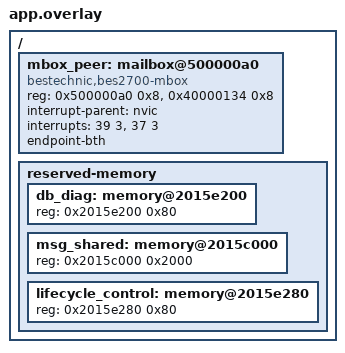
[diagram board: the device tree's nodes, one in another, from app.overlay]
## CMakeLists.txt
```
# SPDX-License-Identifier: Apache-2.0
cmake_minimum_required(VERSION 3.20.0)
find_package(Zephyr REQUIRED HINTS $ENV{ZEPHYR_BASE})
project(bes2700_bth_dual_message)
if(NOT CONFIG_GPIO_BES2700YP)
  target_sources(app PRIVATE
    ${CMAKE_CURRENT_LIST_DIR}/../../../platforms/bes2700yp/boot/service_contract.c
    ${CMAKE_CURRENT_LIST_DIR}/../../../platforms/bes2700yp/resources/contract.c)
endif()
target_sources(app PRIVATE
  ${CMAKE_CURRENT_LIST_DIR}/../../../platforms/bes2700yp/resources/client.c
  ${CMAKE_CURRENT_LIST_DIR}/../../../platforms/bes2700yp/resources/uart_contract.c
  ${CMAKE_CURRENT_LIST_DIR}/../../../platforms/bes2700yp/resources/uart_client.c
  ${CMAKE_CURRENT_LIST_DIR}/../../../platforms/bes2700yp/resources/arbitration_contract.c
  ${CMAKE_CURRENT_LIST_DIR}/../../../platforms/bes2700yp/resources/arbitration_client.c
  ${CMAKE_CURRENT_LIST_DIR}/../../../platforms/bes2700yp/resources/probe.c)
zephyr_get(DUAL_GENERATED_DIR SYSBUILD)
if(CONFIG_BES2700_M55_RESTART)
  target_sources(app PRIVATE src/restart.c
    ${CMAKE_CURRENT_LIST_DIR}/../../../platforms/bes2700yp/lifecycle/manager.c
    ${CMAKE_CURRENT_LIST_DIR}/../../../platforms/bes2700yp/lifecycle/health.c)
else()
  target_sources(app PRIVATE src/main.c)
endif()
if(NOT DUAL_GENERATED_DIR)
  message(FATAL_ERROR "DUAL_GENERATED_DIR is required; use west build --sysbuild")
endif()
target_include_directories(app PRIVATE ${DUAL_GENERATED_DIR})

target_sources(app PRIVATE ${CMAKE_CURRENT_LIST_DIR}/../../../platforms/bes2700yp/ipc/worker.c)
target_compile_definitions(app PRIVATE CC_BTH=1)
target_include_directories(app PRIVATE ${CMAKE_CURRENT_LIST_DIR}/../../../platforms/bes2700yp/ipc)

get_filename_component(bes_workspace ${CMAKE_CURRENT_LIST_DIR}/../../../.. ABSOLUTE)
get_filename_component(bes_build ${PROJECT_BINARY_DIR}/.. ABSOLUTE)
zephyr_compile_options(-ffile-prefix-map=${bes_workspace}=workspace
  -ffile-prefix-map=${bes_build}=build
  $<$<COMPILE_LANGUAGE:ASM>:-Wa,--debug-prefix-map=${bes_workspace}=workspace>
  $<$<COMPILE_LANGUAGE:ASM>:-Wa,--debug-prefix-map=${bes_build}=build>)

if(CONFIG_BES2700YP_GPIO_VALIDATION GREATER 0)
  if(CONFIG_GPIO_BES2700YP_IRQ)
    target_sources(app PRIVATE src/gpio_irq_validation.c)
  elseif(CONFIG_BES2700_M55_RESTART)
    target_sources(app PRIVATE src/gpio_restart.c)
  else()
    target_sources(app PRIVATE src/gpio_validation.c)
  endif()
  if(NOT CONFIG_GPIO_BES2700YP)
    target_sources(app PRIVATE
      ${CMAKE_CURRENT_LIST_DIR}/../../../platforms/bes2700yp/resources/gpio_client.c
      ${CMAKE_CURRENT_LIST_DIR}/../../../platforms/bes2700yp/resources/gpio_contract.c)
  endif()
endif()
```

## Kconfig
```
# SPDX-License-Identifier: Apache-2.0

mainmenu "BES2700YP dual-core validation"
source "Kconfig.zephyr"
config DUAL_CC_PAIR
 hex "Message image pair identity"
 default 0
config DUAL_M55_BUILD
 hex "M55 image source identity"
 default 0

config BTH_LOG_PREFIX
 bool
 default y
config DUAL_DURATION_SECONDS
 int "Dual heartbeat duration in seconds"
 range 600 3610
 default 3610

config DUAL_IPC_SECONDS
 int "Active concurrent traffic duration"
 range 600 3600
 default 3600

config DUAL_MSG_MODE
 int "Message validation: 1=sequential, 2=concurrent, 3=negative"
 range 1 3
 default 1

config BES2700_M55_RESTART
 bool "Validate RAM-retained M55 CPU restart"
 default n

config BES2700_M55_FAULT_CASE
 int "M55 fault injection: 0=off, 1=READY, 2=heartbeat, 3=IPC, 4=QUIESCE, 5=fatal, 6=lost fatal"
 range 0 6
 default 0
 help
   Validation only. Nonzero values require the retained-RAM lifecycle.
   Select a controlled peer fault in the validation application only.

config BES2700_M55_RECOVERY
 bool "Validate one M55 recovery after isolation"
 depends on BES2700_M55_RESTART && BES2700_M55_FAULT_CASE > 0
 default n
 help
   Rebuild the BTH worker and reload M55 once with a new session.
   Inject only in session 1; failed recovery remains isolated.

config BES2700_M55_RECOVERY_FAIL_STEP
 int "Recovery failure injection: 0=off, 1=REPARK, 3=load, 5=new READY"
 range 0 5
 default 0
 help
   Validation only. Values 1 and 3 inject an operation failure before
   touching hardware or loading RAM. Value 5 stops the replacement
   M55 before READY. Profiles reject other nonzero values.
```

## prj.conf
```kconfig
CONFIG_BOOT_BANNER=n
CONFIG_LOG=n
CONFIG_PRINTK=n
CONFIG_CONSOLE=n
CONFIG_ASSERT=y
CONFIG_INIT_STACKS=y
CONFIG_THREAD_STACK_INFO=y
CONFIG_STACK_SENTINEL=y
CONFIG_TICKLESS_KERNEL=n
CONFIG_SYS_CLOCK_TICKS_PER_SEC=1000
CONFIG_MAIN_STACK_SIZE=3072
CONFIG_ISR_STACK_SIZE=2048
CONFIG_PM=n
CONFIG_ARM_MPU=n
CONFIG_HW_STACK_PROTECTION=n
CONFIG_FPU=n
CONFIG_SERIAL=n

CONFIG_MBOX=y
CONFIG_MBOX_BES2700=y
```

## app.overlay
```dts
/* Copyright The Zephyr Project Contributors */
/* SPDX-License-Identifier: Apache-2.0 */

/ {
	mbox_peer: mailbox@500000a0 {
		compatible = "bestechnic,bes2700-mbox";
		reg = <0x500000a0 0x8>, <0x40000134 0x8>;
		reg-names = "sys", "bth";
		interrupt-parent = <&nvic>;
		interrupts = <39 3>, <37 3>;
		endpoint-bth;
		interrupt-names = "rx", "tx-done";
		#mbox-cells = <1>;
		status = "okay";
	};
};

/ { reserved-memory { db_diag: memory@2015e200 { reg = <0x2015e200 0x80>; }; }; };
/ { reserved-memory { msg_shared: memory@2015c000 { reg = <0x2015c000 0x2000>; }; }; };

/* Last shared writer publishes quiescence before CPU reset. */
/ { reserved-memory { lifecycle_control: memory@2015e280 { reg = <0x2015e280 0x80>; }; }; };
```

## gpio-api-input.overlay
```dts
/* SPDX-License-Identifier: Apache-2.0 */
&aon_gpio {
	status = "okay";
	gpio-reserved-ranges = <0 16>;
};
```

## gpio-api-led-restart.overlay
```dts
/* SPDX-License-Identifier: Apache-2.0 */
&aon_gpio {
	status = "okay";
};
```

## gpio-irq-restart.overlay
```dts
/* SPDX-License-Identifier: Apache-2.0 */
&aon_gpio {
	status = "okay";
	interrupt-parent = <&nvic>;
	interrupts = <44 3>;
	gpio-reserved-ranges = <0 16>;
};
```

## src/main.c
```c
/* SPDX-License-Identifier: Apache-2.0 */
#include <zephyr/kernel.h>
#include <cmsis_core.h>
#include <bes2700_dual_boot.h>
#include <bes2700_dual_image.h>
#include "bth_contract.h"
#include "m55_payload.h"
#include "message.h"
#include <bes2700_dual_doorbell.h>
#include <bes2700_observation.h>
#include <bes2700yp_resources.h>
#if CONFIG_BES2700YP_GPIO_VALIDATION
#include <bes2700yp_gpio_validation.h>
#endif
#define SECONDS CONFIG_DUAL_DURATION_SECONDS
BUILD_ASSERT(SECONDS==(CONFIG_DUAL_MSG_MODE!=2?600:CONFIG_DUAL_IPC_SECONDS+10));
_Static_assert(BTH_LOG_ADDR >= DUAL_HW_ADDR + sizeof(struct dual_hw), "log/hardware overlap");
_Static_assert(BTH_LOG_ADDR + sizeof(struct bth_log_clock) <= BTH_DIAG_BASE + 0x1000, "log page overflow");
static int (*service)(uint32_t, uint32_t);
static uint32_t parked;
static volatile uint32_t timer_count;
static void tick(struct k_timer *t) { ARG_UNUSED(t); timer_count++; bth_log_poll(); }
K_TIMER_DEFINE(timer, tick, NULL);
static void field(const char *name, uint32_t n) { bth_puts(name); bth_dec(n); }
static void stage(uint32_t id, uint32_t rc)
{ bth_log_begin(rc?'E':'I',"LOADER","MAIN"); bth_puts("zephyr_dual stage"); field(" id=",id); field(" rc=",rc); bth_end(); }
static void finish(uint32_t samples, uint32_t rc)
{
#if CONFIG_BES2700YP_GPIO_VALIDATION
 bes_gpio_validation_end();
#endif
 q_stop();
 k_timer_stop(&timer);
 if(CONFIG_DUAL_MSG_MODE==2 || rc) {
  bth_log_begin(rc?'E':'I',"KERN","MAIN");
  bth_puts("zephyr_dual result");field(" pass=",rc==0);field(" samples=",samples);field(" rc=",rc);bth_end();
 }
 /* Do not touch shared RAM after stopping the peer. Power remains enabled. */
 if (parked && service) { (void)service(DUAL_STOP,0); }
 /* The periodic clock sampler has stopped; future faults must print NA. */
 bth_log_reset();
}
static void observe_begin(const char *kind, uint32_t rc)
{
 bth_log_begin(rc?'E':'I',"OBSERVE","MAIN");bth_puts("zephyr_observe ");bth_puts(kind);
}
/* Workers have finished. Read the actual AXI publications again, including
 * their seqlocks, instead of accepting only the cached final report. */
static int observe_traffic(const struct q_report *report)
{
 if(!report->finished || report->rc || !report->session) { return 95; }
 for(unsigned side=0;side<2;side++) {
  volatile struct bi_ring *ring=(void *)(uintptr_t)(BI_BASE+4096U*side);
  if(!bi_guards_ok(ring) || ring->head!=ring->tail) { return 95; }
  volatile struct q_state *shared=&ring->state;
  struct q_state copy;uint32_t seq=shared->seq;__DMB();
  if(seq&1) { return 95; }
  uint32_t *d=(void *)&copy;volatile uint32_t *src=(void *)shared;
  for(unsigned i=0;i<sizeof(copy)/4;i++) { d[i]=src[i]; }
  __DMB();if(seq!=shared->seq || copy.seq!=seq) { return 95; }
  const struct q_state *expected=side?&report->m55:&report->bth;
#define CHECK_TERMINAL(n) if(copy.n!=expected->n) { return 95; }
  Q_FIELDS(CHECK_TERMINAL)
#undef CHECK_TERMINAL
  if(copy.error || copy.guard!=Q_META_GUARD) { return 95; }
 }
 return 0;
}
static int observe_checkpoint(struct bes_observation *o, unsigned scope, uint32_t ms,
                              uint32_t samples, const struct q_report *report)
{
 int rc=observe_traffic(report);
 observe_begin("traffic",rc);field(" scope=",scope);field(" session=",report->session);
 field(" finished=",report->finished);field(" live=",!rc);field(" rc=",rc);bth_end();
 observe_begin("result",rc);field(" version=",BES_OBSERVATION_VERSION);field(" scope=",scope);
 field(" pass=",!rc);field(" session=",report->session);field(" functional_ms=",o->functional_ms);
 field(" ms=",ms);field(" samples=",samples);field(" rc=",rc);bth_end();
 return rc;
}
static int read_peer(struct dual_status *s)
{
 for (unsigned retry=0; retry<1000; retry++) {
  uint32_t seq=DUAL_STATUS->seq;
  if (seq&1) { continue; }
  __DMB();
  uint32_t *dst=(uint32_t *)s; volatile uint32_t *src=(volatile uint32_t *)DUAL_STATUS;
  for (unsigned i=0; i<sizeof(*s)/4; i++) { dst[i]=src[i]; }
  __DMB();
  if (seq==DUAL_STATUS->seq && seq==s->seq) { return 0; }
 }
 return -1;
}
static void diagnostics(uint32_t id, uint32_t elapsed, uint32_t good, uint32_t bad)
{
 int hr=service(DUAL_SNAPSHOT,DUAL_HW_ADDR);
 bth_log_begin(hr?'E':'I',"LOADER","MAIN");
 bth_puts("zephyr_dual hw"); field(" id=",id); field(" rc=",hr?1:0);
 const volatile struct dual_hw *h=DUAL_HW;
#define HW(name) bth_field(" " #name "=",h->name)
 HW(phase); HW(core_vtor); HW(reset_set); HW(reset_clr); HW(ram_sel0); HW(ram_sel1);
 HW(oclk); HW(oreset); HW(sysclk); HW(vector_sp); HW(vector_pc); HW(release_sp); HW(release_pc);
#undef HW
 bth_end();
 /* Trace is for localization. Raw values can change while peer runs. */
 struct dual_trace d;
 volatile uint32_t *src=(void *)DUAL_TRACE;
 uint32_t *dst=(void *)&d;
 for (unsigned i=0;i<sizeof(d)/4;i++) { dst[i]=src[i]; }
 __DMB();
 uint32_t stable=d.stage==DUAL_TRACE->stage;
 bth_log_begin('I',"LOADER","MAIN");
 bth_puts("zephyr_dual diag"); field(" id=",id); field(" elapsed=",elapsed);
 field(" reads=",good); field(" retries=",bad); field(" stable=",stable);
 bth_field(" seq=",DUAL_STATUS->seq); bth_field(" magic=",DUAL_STATUS->magic);
#define TRACE(name) bth_field(" " #name "=",d.name)
 TRACE(stage); TRACE(cpuid); TRACE(vtor); TRACE(msp); TRACE(psp); TRACE(control);
 TRACE(primask); TRACE(basepri); TRACE(ccr); TRACE(mpu); TRACE(cpacr); TRACE(cfsr);
 TRACE(hfsr); TRACE(shcsr); TRACE(mmfar); TRACE(bfar); TRACE(icsr); TRACE(reason);
 TRACE(msplim); TRACE(psplim); TRACE(pc); TRACE(lr); TRACE(xpsr); TRACE(esf_valid);
#undef TRACE
 bth_end();
}
static int peer_ok(const struct dual_status *s)
{
 return s->magic==DUAL_MAGIC && s->layout==DUAL_LAYOUT && s->build==M55_BUILD_ID &&
        s->stage==2 && s->hz==DUAL_HZ && s->guard==DUAL_GUARD && !s->error &&
        (s->cpuid&0xff00fff0U)==0x4100d220U && s->vtor==DUAL_ITCM && s->control==2 &&
        !s->primask && !s->basepri && !s->mpu && !(s->ccr & ((1U<<16)|(1U<<17))) && s->stack>=128;
}
int main(void)
{
 bth_stage("main");
 if (bes_resource_probe(0)) { finish(0,96); return 0; }
 bth_log_begin('I',"LOADER","MAIN");
 bth_puts("zephyr_dual begin version=3 test=8"); bth_field(" build=",BTH_DIAG->build);
 bth_field(" m55_build=",M55_BUILD_ID); bth_field(" layout=",DUAL_LAYOUT);
 field(" duration=",SECONDS); field(" bth_hz=",BTH_DIAG->cpu_hz); field(" m55_hz=",DUAL_HZ); bth_end();
 if (!bth_guards_ok() || SCB->CPUID!=0x630f1321 || SCB->VTOR!=BTH_CODE_BASE ||
     __get_CONTROL()!=2 || __get_IPSR() || __get_PRIMASK() || __get_BASEPRI() || BTH_DIAG->cpu_hz!=DUAL_HZ) {
  finish(0,80); return 0;
 }
 const volatile struct dual_service *api=(void *)DUAL_SERVICE_ADDR;
 uint32_t fn=api->dispatch;
 if (dual_service_validate(api)) { finish(0,81); return 0; }
 service=(void *)(uintptr_t)fn;
 int rc=dual_image_check(m55_payload,sizeof(m55_payload),M55_PAYLOAD_CRC);
 stage(1,rc); if (rc) { finish(0,82); return 0; }
 stage(2,0); /* before power/clock operations, so a stalled HAL call is visible */
 rc=service(DUAL_PREPARE,0); stage(3,rc ? 1:0);
 if (rc) { finish(0,83); return 0; }
 k_sleep(K_MSEC(2));
 rc=service(DUAL_PARK,0); stage(4,rc ? 1:0);
 if (rc) { finish(0,84); return 0; } parked=1;
 k_sleep(K_MSEC(2));
 volatile uint32_t *clear=(void *)DUAL_SHARED_ADDR;
 for (unsigned i=0;i<sizeof(struct dual_status)/4;i++) { clear[i]=0; }
 clear=(void *)DUAL_TRACE_ADDR;
 for (unsigned i=0;i<sizeof(struct dual_trace)/4;i++) { clear[i]=0; }
 /* Reset the separate IPC region only while the peer remains parked. */
 clear=(void *)BES_DB_ADDR;
 for (unsigned i=0;i<0x80/4;i++) { clear[i]=0; }
 clear[0x7c/4]=0xdb08bafe;
 q_prepare(BTH_DIAG->build,bth_ticks());
 __DSB(); diagnostics(0,0,0,0);
 /* M55 is executing only the DTCM +8 WFI stub. No load segment may overwrite it. */
 uint32_t count=dual_u32(m55_payload+28)/12;
 for (uint32_t i=0; i<count; i++) {
  const uint8_t *map=m55_payload+32+i*12;
  uint32_t dst=dual_u32(map), src=dual_u32(map+4), n=dual_u32(map+8);
  volatile uint32_t *out=(void *)(uintptr_t)dst;
  for (uint32_t j=0;j<n;j+=4) { out[j/4]=dual_u32(m55_payload+src+j); }
  __DSB();
  if (dual_crc((const uint8_t *)(uintptr_t)dst,n)!=dual_crc(m55_payload+src,n)) { stage(5,1);finish(0,85);return 0; }
 }
 __DSB();stage(5,0);
 rc=service(DUAL_RELEASE,DUAL_TRAMPOLINE|1);stage(6,rc?1:0);
 if (rc) { finish(0,86); return 0; }
 if (bes_resource_probe(3)) { finish(0,96); return 0; }
 diagnostics(1,0,0,0);
 struct dual_status peer={0};
 uint32_t handshake=k_uptime_get_32(), reads=0, retries=0;
 uint64_t deadline=k_uptime_get()+2000;
 while (k_uptime_get()<deadline) {
  int read_rc=read_peer(&peer);
  if (read_rc) { retries++; } else { reads++; }
  if (!read_rc && peer.magic==DUAL_MAGIC && peer.stage==2) { break; }
  if (peer.stage==255) { break; }
  k_sleep(K_MSEC(1));
 }
 bth_log_begin(peer.error?'E':'I',"LOADER","MAIN");
 bth_puts("zephyr_dual peer"); bth_field(" cpuid=",peer.cpuid); bth_field(" vtor=",peer.vtor);
 bth_field(" build=",peer.build);field(" stage=",peer.stage);field(" error=",peer.error);
 field(" mpu=",peer.mpu);bth_field(" ccr=",peer.ccr);field(" control=",peer.control);bth_end();
 diagnostics(2,k_uptime_get_32()-handshake,reads,retries);
 if (!peer_ok(&peer) || service(DUAL_CHECK_CLOCK,0)) { stage(7,1);finish(0,87);return 0; }stage(7,0);
 bth_log_begin('I',"IPC","MAIN");
 bth_puts("zephyr_msg begin version=2 channel=1");field(" duration=",CONFIG_DUAL_IPC_SECONDS);
 field(" progress_period=",10);field(" mode=",CONFIG_DUAL_MSG_MODE);field(" layout=",Q_LAYOUT);
 field(" pair=",CONFIG_DUAL_CC_PAIR);field(" depth=",BI_DEPTH);field(" payload=",BI_PAYLOAD);bth_end();
#if CONFIG_BES2700YP_GPIO_VALIDATION
 if(bes_gpio_validation_init()){finish(0,97);return 0;}
#endif
 q_start();bool db_printed=false;struct bes_observation observation={0};
 uint32_t start_ms=k_uptime_get_32(), start_raw=bth_ticks(), prev_cycles=peer.cycles;
 uint32_t base_peer_ms=peer.ms, base_beat=peer.beat, last_beat=peer.beat;
 uint64_t peer_cycles=0, ticks=0;
 k_timer_start(&timer,K_MSEC(100),K_MSEC(100));
 const uint32_t limit=CONFIG_DUAL_MSG_MODE==2?SECONDS:BES_OBSERVATION_LIMIT_MS/1000;
 for (uint32_t i=0;i<=limit;i++) {
  if (i) {
#if CONFIG_BES2700YP_GPIO_VALIDATION
   while(k_uptime_get()<(uint64_t)start_ms+i*1000){
    int grc=bes_gpio_validation_poll();
    if(grc){finish(i,grc);return 0;}
    k_sleep(K_MSEC(10));
   }
   int grc=bes_gpio_validation_poll();
   if(grc){finish(i,grc);return 0;}
#else
   k_sleep(K_TIMEOUT_ABS_MS((uint64_t)start_ms+i*1000));
#endif
  }
  if (CONFIG_DUAL_MSG_MODE==2 && i==SECONDS) { k_timer_stop(&timer); }
  uint32_t elapsed=k_uptime_get_32()-start_ms, raw=bth_ticks();
  ticks+=(uint32_t)(raw-start_raw); start_raw=raw;
  rc=0;
  if (read_peer(&peer) || !peer_ok(&peer)) { rc=88; }
  peer_cycles+=(uint32_t)(peer.cycles-prev_cycles);prev_cycles=peer.cycles;
  uint32_t pm=peer.ms-base_peer_ms, beat=peer.beat-base_beat;
  int32_t skew=(int32_t)(pm-elapsed);
  uint64_t expect=(uint64_t)elapsed*6000;
  uint64_t diff=ticks>expect ? ticks-expect:expect-ticks;
  uint64_t mexpect=(uint64_t)pm*24000;
  uint64_t mdiff=peer_cycles>mexpect ? peer_cycles-mexpect:mexpect-peer_cycles;
  size_t stack=0;
  if (k_thread_stack_space_get(k_current_get(),&stack) || stack<128 || !bth_guards_ok() || BTH_DIAG->error) { rc=89; }
  if (i && (peer.beat<=last_beat || skew < -250 || skew >250 || elapsed<i*1000 || elapsed>i*1000+100 ||
      diff>expect/100 || mdiff>MAX(24000ULL,mexpect/100) || beat+3<pm/100 || beat>pm/100+3 ||
      timer_count+2<elapsed/100 || timer_count>elapsed/100+2 || service(DUAL_CHECK_CLOCK,0))) { rc=90; }
  last_beat=peer.beat;
  bth_log_begin(rc?'E':'I',"KERN","MAIN");
  bth_puts("zephyr_dual sample");field(" id=",i);field(" ms=",elapsed);bth_puts(" ticks=");bth_dec64(ticks);
  field(" timer=",timer_count);field(" m55_ms=",pm);field(" beat=",beat);
  field(" cycles_hi=",peer_cycles>>32);field(" cycles_lo=",peer_cycles);
  field(" bth_stack=",stack);field(" m55_stack=",peer.stack);
  field(" guards=",bth_guards_ok() && peer.guard==DUAL_GUARD);field(" rc=",rc);bth_end();
#if CONFIG_BES2700YP_GPIO_VALIDATION
  bes_gpio_validation_timing(i,rc);
#endif
  struct q_report db;q_snapshot(&db);
  if(i && i%10==0 && i<CONFIG_DUAL_IPC_SECONDS && CONFIG_DUAL_MSG_MODE==2) {
   const struct q_state *lanes[2]={&db.bth,&db.m55};
   if(db.finished || !db.session || db.bth.elapsed+2500U<elapsed ||
      db.m55.elapsed+2500U<elapsed || db.bth.phase!=Q_RUNNING || db.m55.phase!=Q_RUNNING) { rc=94; }
   for(unsigned side=0;side<2;side++) {
    bth_log_begin(rc?'E':'I',"IPC","MAIN");bth_puts("zephyr_msg progress");
    field(" sample=",i);field(" side=",side);
#define CS_PROGRESS(name) field(" " #name "=",lanes[side]->name);
    Q_FIELDS(CS_PROGRESS)
#undef CS_PROGRESS
    field(" error=",lanes[side]->error);field(" guard=",lanes[side]->guard);bth_end();
   }
  }
  if(db.finished && !db_printed) {
   if(CONFIG_DUAL_MSG_MODE==3) {
    for(unsigned c=0;c<11;c++) {
     bth_log_begin(db.rc?'E':'I',"IPC","MAIN");bth_puts("zephyr_msg case");
     field(" id=",db.cases[c].id);field(" expected=",db.cases[c].expected);
     field(" bth=",db.cases[c].bth);field(" m55=",db.cases[c].m55);bth_end();
    }
   }
   const struct q_state *lanes[2]={&db.bth,&db.m55};
   for(unsigned side=0;side<2;side++) {
    bth_log_begin(db.rc?'E':'I',"IPC","MAIN");bth_puts("zephyr_msg endpoint");field(" side=",side);
#define CC_PRINT(name) field(" " #name "=",lanes[side]->name);
    Q_FIELDS(CC_PRINT)
#undef CC_PRINT
    field(" error=",lanes[side]->error);field(" guard=",lanes[side]->guard);bth_end();
   }
   bth_log_begin(db.rc?'E':'I',"IPC","MAIN");bth_puts("zephyr_msg result");
   field(" finished=",db.finished);field(" rc=",db.rc);field(" session=",db.session);
   bth_end();db_printed=true;
  }
  if(db_printed && CONFIG_DUAL_MSG_MODE!=2 && !db.rc && !rc && !observation.functional
#if CONFIG_BES2700YP_GPIO_VALIDATION
     && bes_gpio_validation_done()
#endif
  ) {
#if CONFIG_BES2700YP_GPIO_VALIDATION
    int grc=bes_gpio_validation_functional();
    if(grc){finish(i+1,grc);return 0;}
#endif
    observation.functional_ms=k_uptime_get_32()-start_ms;observation.functional=true;
    observe_begin("functional",0);field(" version=",BES_OBSERVATION_VERSION);
    field(" ms=",observation.functional_ms);field(" session=",db.session);field(" rc=",0);bth_end();
  }
  if(db.finished && db.rc) { rc=92; }
  if(i>=(CONFIG_DUAL_MSG_MODE!=2?590:CONFIG_DUAL_IPC_SECONDS+5) && !db.finished) { rc=93; }
  if(CONFIG_DUAL_MSG_MODE!=2 && !rc) {
   unsigned scope=bes_observation_due(&observation,elapsed);
   if(scope) {
    rc=observe_checkpoint(&observation,scope,elapsed,i+1,&db);
    observation.short_done=true;
    if(!rc && scope==1 && bes_observation_due(&observation,elapsed)==2) {
     scope=2;rc=observe_checkpoint(&observation,scope,elapsed,i+1,&db);
    }
    if(scope==2 || rc) { finish(i+1,rc);return 0; }
   }
  }
  if (rc || i==limit) { finish(i+1,rc?rc:CONFIG_DUAL_MSG_MODE==2?0:96); return 0; }
 }
 return 0;
}
```

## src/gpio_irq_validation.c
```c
/* SPDX-License-Identifier: Apache-2.0 */
#include <zephyr/kernel.h>
#include <zephyr/drivers/gpio.h>
#include <cmsis_core.h>
#include <bes2700yp_gpio_irq.h>
#include <bes2700yp_gpio_irq_validation.h>
#include <bes2700yp_gpio_validation.h>
#include "bth_contract.h"

#define KEYS BES_GPIO_IRQ_KEYS
#define QUEUE_SIZE 32U
static const struct gpio_dt_spec keys[2] = {
 GPIO_DT_SPEC_GET(DT_ALIAS(sw0), gpios), GPIO_DT_SPEC_GET(DT_ALIAS(sw1), gpios),
};
struct irq_event { uint32_t pins; };
static struct irq_event events[QUEUE_SIZE];
static volatile uint32_t head, tail, overflow;
static struct gpio_callback callback;
static struct bes_gpio_button buttons[2];
static uint32_t credits[2], down_credit[2], cycles[2];
static uint32_t stage, mode, target, start_ms, reported, failure;
static int access_error;
static bool initialized, complete, functional_reported;
static struct bes_gpio_irq_state baseline;
static struct bes_gpio_irq_stats before;

static void field(const char *name, uint32_t value) { bth_puts(name); bth_dec(value); }
static void begin(const char *name)
{
 bth_log_begin(failure?'E':'I', "GPIO", "MAIN"); bth_puts("zephyr_gpio_irq "); bth_puts(name);
 field(" stage=", stage);
}
static void on_irq(const struct device *dev, struct gpio_callback *cb, uint32_t pins)
{
 ARG_UNUSED(dev); ARG_UNUSED(cb);
 uint32_t next=head+1U;
 if(next-tail>QUEUE_SIZE){overflow=1;return;}
 events[head%QUEUE_SIZE].pins=pins;__DMB();head=next;
}
static int fail(uint32_t rc)
{
 failure=rc;begin("failure");field(" rc=",rc);field(" api_error=",(uint32_t)-access_error);bth_end();
 if(initialized){
  struct bes_gpio_irq_state state;
  int read=bes_gpio_irq_get_state(keys[0].port,&state);
  begin("diagnostic");field(" read_error=",(uint32_t)-read);
  if(!read){
#define DIAG(n) field(" " #n "=",state.n);
   BES_GPIO_IRQ_FIELDS(DIAG)
#undef DIAG
  }
  bth_end();
 }
 return (int)rc;
}
static int snapshot(uint32_t checkpoint)
{
 struct bes_gpio_irq_state s;
 struct bes_gpio_irq_stats stats;
 int rc=bes_gpio_irq_get_state(keys[0].port,&s);
 if(!rc){rc=bes_gpio_irq_get_stats(keys[0].port,&stats);}
 uint32_t enabled=mode?KEYS:0U;
 if(rc || stats.fault || overflow){return fail(101);}
 /* Only the two granted IRQ bits and the GPIO wake gate may change. */
 if((s.enabled&KEYS)!=enabled || (s.route&KEYS)!=enabled ||
    (s.masked&KEYS)!=(mode?0U:KEYS) || (s.edge&KEYS)!=KEYS ||
    (s.rising&KEYS)!=((mode==2U || mode==0U)?KEYS:0U) || (s.debounce&KEYS) ||
    (s.directions&KEYS) || !(s.wake_mask&1U) || (s.wake_status&~1U) ||
    (s.bth_status&~KEYS) || stats.enabled!=enabled ||
    ((s.enabled^baseline.enabled)&~KEYS) || ((s.masked^baseline.masked)&~KEYS) ||
    ((s.edge^baseline.edge)&~KEYS) || ((s.rising^baseline.rising)&~KEYS) ||
    ((s.debounce^baseline.debounce)&~KEYS) || ((s.route^baseline.route)&~KEYS) ||
    ((s.wake_mask^baseline.wake_mask)&~1U) || s.sys_route!=baseline.sys_route ||
    s.btc_route!=baseline.btc_route || s.sens_route!=baseline.sens_route ||
    s.directions!=baseline.directions){return fail(102);}
 begin("snapshot");field(" checkpoint=",checkpoint);field(" mode=",mode);
 field(" enabled=",s.enabled);field(" mask=",s.masked);field(" edge=",s.edge);
 field(" rising=",s.rising);field(" route=",s.route);field(" wake=",s.wake_mask);
 field(" irq=",stats.interrupts);field(" events0=",stats.events0);field(" events1=",stats.events1);
 field(" spurious=",stats.spurious);field(" max_cycles=",stats.max_ticks);
 field(" overflow=",overflow);field(" fault=",stats.fault);field(" rc=",0);bth_end();
 return 0;
}
static int set_mode(uint32_t wanted)
{
 /* Disable both before changing polarity. No pin direction/mux changes. */
 for(unsigned i=0;i<2;i++){
  access_error=gpio_pin_interrupt_configure(keys[i].port,keys[i].pin,GPIO_INT_DISABLE);
  if(access_error){return fail(103);}
 }
 for(unsigned i=0;i<2 && wanted;i++){
  access_error=gpio_pin_interrupt_configure(keys[i].port,keys[i].pin,
      wanted==2U?GPIO_INT_EDGE_RISING:GPIO_INT_EDGE_FALLING);
  if(access_error){return fail(103);}
 }
 mode=wanted;return 0;
}
int bes_gpio_irq_validation_start(uint32_t next)
{
 stage=next;complete=false;target=next==3U||next==4U?1U:10U;
 if(!initialized){
  if(!gpio_is_ready_dt(&keys[0]) || keys[0].port!=keys[1].port){return fail(104);}
  for(unsigned i=0;i<2;i++){
   if(gpio_pin_configure_dt(&keys[i],GPIO_INPUT)){return fail(104);}
  }
  if(bes_gpio_irq_get_state(keys[0].port,&baseline)){return fail(104);}
  gpio_init_callback(&callback,on_irq,KEYS);
  if(gpio_add_callback(keys[0].port,&callback)){return fail(104);}
  initialized=true;
 }
 /* Post-restart stage deliberately retains hardware state and registration. */
 if(next!=11U && set_mode(next==2U?2U:next==3U?0U:1U)){return (int)failure;}
 unsigned key=irq_lock();tail=head;irq_unlock(key);
 for(unsigned i=0;i<2;i++){
  buttons[i]=(struct bes_gpio_button){0};credits[i]=down_credit[i]=cycles[i]=0;
 }
 if(bes_gpio_irq_get_stats(keys[0].port,&before)){return fail(105);}
 start_ms=k_uptime_get_32();reported=0;
 begin("begin");field(" version=",1);field(" mode=",mode);field(" target=",target);
 field(" pins=",KEYS);field(" irq=",before.interrupts);
 field(" events0=",before.events0);field(" events1=",before.events1);field(" rc=",0);bth_end();
 if(snapshot(0)){return (int)failure;}
 begin("prompt");bth_puts(" release_both_then_press_and_release_each_key");field(" count=",target);bth_end();
 return 0;
}
int bes_gpio_irq_validation_poll(void)
{
 if(failure){return (int)failure;}
 struct bes_gpio_irq_stats stats;
 if(bes_gpio_irq_get_stats(keys[0].port,&stats) || stats.fault || overflow){return fail(106);}
 if(complete){return 0;}
 uint32_t now=k_uptime_get_32();
 if(now-start_ms>180000U){return fail(107);}
 /* One producer (IRQ 44), one consumer. At most a queue's worth per poll. */
 uint32_t limit=head;__DMB();
 while(tail!=limit){
  uint32_t pins=events[tail%QUEUE_SIZE].pins;
  if(!pins || (pins&~KEYS)){return fail(108);}
  for(unsigned i=0;i<2;i++){if(pins&(1U<<(16+i))){credits[i]++;}}
  __DMB();tail++;
 }
 gpio_port_value_t inputs;
 if(gpio_port_get_raw(keys[0].port,&inputs)){return fail(109);}
 for(unsigned i=0;i<2;i++){
  struct bes_gpio_button *b=&buttons[i];
  uint32_t prior_press=b->presses,prior_release=b->releases;
  int changed=bes_gpio_button_update(b,!!(inputs&(1U<<(16+i))),now);
  if(changed && b->presses!=prior_press){
   down_credit[i]=credits[i];credits[i]=0;
  }
  if(changed && b->releases!=prior_release){
   uint32_t evidence=mode==2U?credits[i]:down_credit[i];
   if(mode && !evidence){return fail(110);}
   if(!mode && (stats.events0!=before.events0 || stats.events1!=before.events1)){
    return fail(111);
   }
   cycles[i]++;begin("cycle");field(" pin=",16U+i);field(" count=",cycles[i]);
   field(" mode=",mode);field(" evidence=",evidence);field(" ms=",now-start_ms);
   field(" rc=",0);bth_end();
  }
  if(changed && b->stable){credits[i]=0;down_credit[i]=0;}
 }
 if(cycles[0]>=target && cycles[1]>=target && buttons[0].stable && buttons[1].stable){
  if(snapshot(1)){return (int)failure;}
  if(bes_gpio_irq_get_stats(keys[0].port,&stats)){return fail(112);}
  complete=true;begin("stage_result");field(" pass=",1);field(" mode=",mode);
  field(" count0=",cycles[0]);field(" count1=",cycles[1]);field(" target=",target);
  field(" irq=",stats.interrupts-before.interrupts);
  field(" events0=",stats.events0-before.events0);field(" events1=",stats.events1-before.events1);
  field(" ms=",now-start_ms);field(" rc=",0);bth_end();
 }else if(now-start_ms>=reported+10000U){
  reported=now-start_ms;begin("waiting");field(" count0=",cycles[0]);field(" count1=",cycles[1]);
  field(" target=",target);field(" ms=",reported);bth_end();
 }
 return 0;
}
int bes_gpio_irq_validation_done(void){return complete && !failure;}
int bes_gpio_irq_validation_check(uint32_t checkpoint)
{
 if(!initialized){return fail(113);}
 return snapshot(checkpoint);
}
int bes_gpio_irq_validation_result(void)
{
 if(!complete || failure){return fail(114);}
 functional_reported=true;begin("result");field(" version=",1);field(" pass=",1);field(" rc=",0);bth_end();return 0;
}
void bes_gpio_irq_validation_end(void)
{
 if(!initialized){return;}
 for(unsigned i=0;i<2;i++){(void)gpio_pin_interrupt_configure(keys[i].port,keys[i].pin,GPIO_INT_DISABLE);}
 (void)gpio_remove_callback(keys[0].port,&callback);
}
#ifndef CONFIG_BES2700_M55_RESTART
int bes_gpio_validation_init(void){return bes_gpio_irq_validation_start(1);}
int bes_gpio_validation_poll(void)
{
 int rc=bes_gpio_irq_validation_poll();
 if(!rc && complete && stage<4U){rc=bes_gpio_irq_validation_start(stage+1U);}
 return rc;
}
int bes_gpio_validation_done(void){return stage==4U && bes_gpio_irq_validation_done();}
int bes_gpio_validation_functional(void){return bes_gpio_irq_validation_result();}
void bes_gpio_validation_timing(uint32_t sample,uint32_t rc)
{
 ARG_UNUSED(rc);
 if(functional_reported){(void)bes_gpio_irq_validation_check(1000U+sample);}
}
void bes_gpio_validation_end(void){bes_gpio_irq_validation_end();}
#endif
```

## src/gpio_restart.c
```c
/* SPDX-License-Identifier: Apache-2.0 */
#include <zephyr/drivers/gpio.h>
#include <zephyr/kernel.h>
#include <bes2700yp_gpio.h>
#include <bes2700yp_gpio_restart.h>
#include "bth_contract.h"

static const struct gpio_dt_spec led = GPIO_DT_SPEC_GET(DT_ALIAS(led0), gpios);
static struct bes_gpio_io io;
static struct bes_gpio_snapshot baseline;
static uint32_t transitions, max_ticks, mask_errors;
static bool configured;

static void field(const char *key, uint32_t value)
{
	bth_puts(key);
	bth_dec(value);
}

static int snapshot(void)
{
	return bes_gpio_call(BES_GPIO_READ, 0, 0, &io);
}

static int preserved(uint32_t phase, uint32_t level)
{
	const struct bes_gpio_snapshot *s = &io.snapshot;

	return s->phase == phase && s->fault == 0 &&
		s->clocks == baseline.clocks && s->resets == baseline.resets &&
		s->irq_enabled == baseline.irq_enabled && s->control == baseline.control &&
		s->mux_keys == baseline.mux_keys &&
		!((s->mux_led ^ baseline.mux_led) & ~(15U << 16)) &&
		!((s->pull_up ^ baseline.pull_up) & ~BES_GPIO_LED) &&
		!((s->pull_down ^ baseline.pull_down) & ~BES_GPIO_LED) &&
		!((s->directions ^ baseline.directions) & ~BES_GPIO_LED) &&
		!((s->outputs ^ baseline.outputs) & ~BES_GPIO_LED) &&
		(s->directions & BES_GPIO_LED) && !(s->mux_led & (15U << 16)) &&
		!((s->pull_up | s->pull_down) & BES_GPIO_LED) &&
		!!(s->outputs & BES_GPIO_LED) == level;
}

static void record(const char *kind, uint32_t round, uint32_t stage,
		   uint32_t sample, int rc)
{
	bth_log_begin(rc ? 'E' : 'I', "GPIO", "MAIN");
	bth_puts("zephyr_gpio_api ");
	bth_puts(kind);
	field(" version=", 1);
	field(" round=", round);
	field(" stage=", stage);
	field(" sample=", sample);
	field(" phase=", io.snapshot.phase);
	field(" fault=", io.snapshot.fault);
#define PRINT(n) bth_field(" " #n "=", io.snapshot.n);
	BES_GPIO_FIELDS(PRINT)
#undef PRINT
	field(" transitions=", transitions);
	field(" max_ticks=", max_ticks);
	field(" mask_errors=", mask_errors);
	field(" rc=", rc < 0 ? (uint32_t)-rc : (uint32_t)rc);
	bth_end();
}

static int check_pad(uint32_t phase, uint32_t level)
{
	int logical = gpio_pin_get_dt(&led);
	int rc = snapshot();

	if (logical < 0) {
		return logical;
	}
	if (rc != 0) {
		return rc;
	}
	if (!preserved(phase, level) || logical != (int)!level ||
	    !!(io.snapshot.inputs & BES_GPIO_LED) != level) {
		return -EIO;
	}
	return 0;
}

int bes_gpio_restart_checkpoint(uint32_t round, uint32_t stage)
{
	uint32_t phase = stage == 0 ? 3 : 4;
	uint32_t ticks;
	int rc;

	if (!gpio_is_ready_dt(&led)) {
		return -ENODEV;
	}
	if (!configured) {
		if (round != 0 || stage != 0) {
			return -EINVAL;
		}
		rc = snapshot();
		if (rc != 0) {
			return rc;
		}
		baseline = io.snapshot;
		record("baseline", 0, 0, 0, 0);
		rc = gpio_pin_configure_dt(&led, GPIO_OUTPUT_INACTIVE);
		if (rc != 0) {
			record("checkpoint", round, stage, 0, rc);
			return rc;
		}
		configured = true;
		k_msleep(10);
	}
	/* Check retention before a new write can conceal a reset-induced change. */
	rc = check_pad(phase, stage == 0 ? 1 : 0);
	if (rc == 0) {
		mask_errors += !!__get_PRIMASK() || !!__get_BASEPRI();
		ticks = bth_ticks();
		rc = stage == 0 ? gpio_pin_toggle_dt(&led) : gpio_pin_set_dt(&led, 0);
		ticks = bth_ticks() - ticks;
		max_ticks = MAX(max_ticks, ticks);
		mask_errors += !!__get_PRIMASK() || !!__get_BASEPRI();
		if (rc == 0) {
			transitions++;
			k_msleep(10);
			rc = check_pad(phase, stage == 0 ? 0 : 1);
		}
	}
	if (mask_errors != 0 && rc == 0) {
		rc = -EPERM;
	}
	record("checkpoint", round, stage, 0, rc);
	return rc;
}

int bes_gpio_restart_observe(uint32_t sample)
{
	int rc = configured && transitions == 22 ? check_pad(4, 1) : -EINVAL;

	record("observe", 10, 2, sample, rc);
	return rc;
}

void bes_gpio_restart_end(void)
{
	if (configured) {
		(void)gpio_pin_set_dt(&led, 0);
	}
}
```

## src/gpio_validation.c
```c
/* SPDX-License-Identifier: Apache-2.0 */
#include <zephyr/kernel.h>
#include <errno.h>
#include "bth_contract.h"
#include <bes2700yp_gpio.h>
#include <bes2700yp_gpio_validation.h>
#ifdef CONFIG_GPIO_BES2700YP
#include <zephyr/drivers/gpio.h>
static const struct gpio_dt_spec key_specs[] = {
 GPIO_DT_SPEC_GET(DT_ALIAS(sw0), gpios), GPIO_DT_SPEC_GET(DT_ALIAS(sw1), gpios)
};
static int native_access(uint32_t op,uint32_t pin,struct bes_gpio_io *out)
{
 if(op==BES_GPIO_INPUT && (pin==16U || pin==17U)){
  return gpio_pin_configure_dt(&key_specs[pin-16U],GPIO_INPUT);
 }
 if(op==BES_GPIO_SAMPLE){
  gpio_port_value_t inputs;
  int rc=gpio_port_get_raw(key_specs[0].port,&inputs);
  if(!rc){out->snapshot.inputs=inputs;}
  return rc;
 }
 /* Full service snapshots remain diagnostics, never a substitute for API IO. */
 if(op==BES_GPIO_READ){return bes_gpio_call(op,0,0,out);}
 return -ENOTSUP;
}
#endif
#define MODE CONFIG_BES2700YP_GPIO_VALIDATION
#define TARGET 10U
#define LIMIT_MS 300000U
static struct bes_gpio_io io, sample_io;
static struct bes_gpio_snapshot baseline;
static struct bes_gpio_button keys[2];
static uint32_t start, next_poll, next_snapshot, led_steps, led_changed, led_level=1;
static uint32_t samples, pad_checks, reported, busy_count, busy_since;
static uint32_t calls[3], max_ticks[3], mask_errors;
static int done, error, led_claimed;
static void field(const char *name,uint32_t n){bth_puts(name);bth_dec(n);}
static void begin(const char *kind,int rc)
{
 bth_log_begin(rc?'E':'I',"GPIO","MAIN");bth_puts("zephyr_gpio ");bth_puts(kind);
}
/* Measure the actual call with the independent fast timer. Never read SysTick
 * CTRL: reading COUNTFLAG would disturb the kernel timer's wrap accounting. */
static int __attribute__((noinline)) gpio_access(uint32_t op,uint32_t pin,uint32_t value,struct bes_gpio_io *out)
{
 uint32_t before_mask=__get_PRIMASK(), before=bth_ticks();
#ifdef CONFIG_GPIO_BES2700YP
 (void)value;
 int rc=native_access(op,pin,out);
 if(rc==-EWOULDBLOCK){rc=-EBUSY;}
#else
 int rc=bes_gpio_call(op,pin,value,out);
#endif
 uint32_t elapsed=bth_ticks()-before, after_mask=__get_PRIMASK();
 unsigned kind=op==BES_GPIO_SAMPLE?0:op==BES_GPIO_READ?1:2;
 calls[kind]++;if(elapsed>max_ticks[kind]){max_ticks[kind]=elapsed;}
 if(before_mask || after_mask){mask_errors++;return -EPERM;}
 return rc;
}
void bes_gpio_validation_timing(uint32_t sample,uint32_t rc)
{
 if(!sample || (!rc && sample!=1U && sample%10U)){return;}
 uint32_t load=SysTick->LOAD,val=SysTick->VAL;
 uint32_t pending=!!(SCB->ICSR&SCB_ICSR_PENDSTSET_Msk);
 uint32_t maximum=MAX(max_ticks[0],MAX(max_ticks[1],max_ticks[2]));
 begin("timing",rc);field(" version=",2);field(" sample=",sample);
 field(" ms=",k_uptime_get_32()-start);field(" calls=",calls[0]+calls[1]+calls[2]);
 field(" sample_calls=",calls[0]);field(" read_calls=",calls[1]);field(" write_calls=",calls[2]);
 field(" max_ticks=",maximum);field(" sample_max_ticks=",max_ticks[0]);
 field(" read_max_ticks=",max_ticks[1]);field(" write_max_ticks=",max_ticks[2]);
 field(" mask_errors=",mask_errors);field(" systick_load=",load);
 field(" systick_val=",val);field(" systick_pending=",pending);field(" rc=",rc);bth_end();
}
static void snapshot(uint32_t stage)
{
 begin("snapshot",0);field(" stage=",stage);field(" phase=",io.snapshot.phase);
 field(" fault=",io.snapshot.fault);
#define PRINT(n) bth_field(" " #n "=",io.snapshot.n);
 BES_GPIO_FIELDS(PRINT)
#undef PRINT
 bth_end();
}
static int preserved(void)
{
 const struct bes_gpio_snapshot *s=&io.snapshot;
 uint32_t changed=BES_GPIO_KEYS|(MODE==2?BES_GPIO_LED:0);
 uint32_t led_mux=MODE==2?(15U<<16):0;
 return s->phase==3 && !s->fault && s->clocks==baseline.clocks && s->resets==baseline.resets &&
  s->irq_enabled==baseline.irq_enabled && s->control==baseline.control &&
  !((s->mux_led^baseline.mux_led)&~led_mux) &&
  !((s->mux_keys^baseline.mux_keys)&~0xffU) &&
  !((s->pull_up^baseline.pull_up)&~changed) &&
  !((s->pull_down^baseline.pull_down)&~changed) &&
  !((s->directions^baseline.directions)&~changed) &&
  !((s->outputs^baseline.outputs)&~(MODE==2?BES_GPIO_LED:0)) &&
  !(s->directions&BES_GPIO_KEYS) && !(s->mux_keys&0xffU) &&
  (s->pull_up&BES_GPIO_KEYS)==BES_GPIO_KEYS && !(s->pull_down&BES_GPIO_KEYS) &&
  (MODE!=2 || ((s->directions&BES_GPIO_LED) && !(s->mux_led&(15U<<16)) &&
   !((s->pull_up|s->pull_down)&BES_GPIO_LED)));
}
static void result(uint32_t ms,int rc)
{
 begin("result",rc);field(" version=",2);field(" mode=",MODE);field(" pass=",!rc);
 field(" ms=",ms);field(" samples=",samples);
 field(" p0=",keys[0].presses);field(" r0=",keys[0].releases);
 field(" p1=",keys[1].presses);field(" r1=",keys[1].releases);
 field(" led_steps=",led_steps);field(" pad_checks=",pad_checks);
 field(" busy=",busy_count);field(" rc=",rc);bth_end();reported=1;
}
int bes_gpio_validation_init(void)
{
 begin("begin",0);
#ifdef CONFIG_GPIO_BES2700YP
 field(" version=",3);field(" api=",1);
#else
 field(" version=",2);
#endif
 bth_field(" build=",BTH_DIAG->build);
 field(" mode=",MODE);field(" target=",TARGET);field(" poll_ms=",10);
 field(" snapshot_ms=",1000);field(" debounce_ms=",50);field(" timeout_ms=",LIMIT_MS);bth_end();
#ifdef CONFIG_GPIO_BES2700YP
 int rc=gpio_is_ready_dt(&key_specs[0]) && gpio_is_ready_dt(&key_specs[1])?0:-ENODEV;
#else
 int rc=bes_gpio_connect();
#endif
 if(!rc){rc=gpio_access(BES_GPIO_READ,0,0,&io);}
 if(rc){begin("error",rc);field(" stage=",0);field(" rc=",-rc);bth_end();return 97;}
 baseline=io.snapshot;snapshot(0);
 rc=gpio_access(BES_GPIO_INPUT,16,0,&io);
 if(!rc){rc=gpio_access(BES_GPIO_INPUT,17,0,&io);}
 if(!rc && MODE==2){rc=gpio_access(BES_GPIO_OUTPUT,12,1,&io);led_claimed=!rc;}
 if(rc){begin("error",rc);field(" stage=",1);field(" rc=",-rc);bth_end();return 97;}
#ifdef CONFIG_GPIO_BES2700YP
 rc=gpio_access(BES_GPIO_READ,0,0,&io);
 if(rc){return 97;}
#endif
 snapshot(1);
 if(!preserved()){return 98;}
 start=k_uptime_get_32();next_snapshot=1000;
 begin("waiting",0);field(" pins=",BES_GPIO_KEYS);field(" cycles_each=",TARGET);bth_end();
 return 0;
}
int bes_gpio_validation_poll(void)
{
 uint32_t ms=k_uptime_get_32()-start;
 if(error){return error;}
 if(ms<next_poll){return 0;}next_poll=ms+10;
 int rc=gpio_access(BES_GPIO_SAMPLE,0,0,&sample_io);
 if(rc==-EBUSY){
  if(!busy_since){busy_since=ms+1;}busy_count++;
  if(ms+1-busy_since<100U){return 0;}
 }
 if(rc){error=99;}
 else {
  ms=k_uptime_get_32()-start;busy_since=0;samples++;
#ifndef CONFIG_GPIO_BES2700YP
  if(sample_io.snapshot.fault || sample_io.snapshot.phase!=3){error=98;}
#endif
  if(ms>=next_snapshot && !error){
   rc=gpio_access(BES_GPIO_READ,0,0,&io);
   if(rc){error=99;}else if(!preserved()){error=98;}
   next_snapshot=ms+1000;
  }
  if(MODE==2 && ms-led_changed>=10U){
   if(!!(sample_io.snapshot.inputs&BES_GPIO_LED)!=led_level){error=100;}
   else {pad_checks++;}
  }
  for(unsigned i=0;i<2 && !done && !error;i++){
   uint32_t level=(sample_io.snapshot.inputs>>(16U+i))&1U;
   if(bes_gpio_button_update(&keys[i],level,ms)){
    begin("key",0);field(" pin=",16U+i);field(" ms=",ms);field(" level=",level);
    field(" presses=",keys[i].presses);field(" releases=",keys[i].releases);bth_end();
   }
  }
  if(MODE==2 && led_steps<20U && ms>=(led_steps+1U)*1000U && !error){
   led_level^=1U;rc=gpio_access(BES_GPIO_WRITE,12,led_level,&io);
   if(rc){error=101;}else if(!preserved()){error=98;}else {
    led_steps++;led_changed=ms;
    begin("led",0);field(" ms=",ms);field(" step=",led_steps);
    field(" pin=",12);field(" level=",led_level);bth_end();
   }
  }
 }
 if(!done && !error && keys[0].releases>=TARGET && keys[1].releases>=TARGET &&
    keys[0].stable && keys[1].stable && (MODE!=2 ||
     (led_steps==20 && pad_checks>=20 && ms-led_changed>=10U))){done=1;}
 if(!done && ms>=LIMIT_MS && !error){error=110;}
 if(error && !reported){result(ms,error);}
 return error;
}
int bes_gpio_validation_done(void){return done && !error;}
int bes_gpio_validation_functional(void)
{
 if(done && !reported){
  int rc=gpio_access(BES_GPIO_READ,0,0,&io);
  if(rc){error=99;}else if(!preserved()){error=98;}
  if(!error){snapshot(2);}result(k_uptime_get_32()-start,error);
 }
 return error;
}
void bes_gpio_validation_end(void)
{
 if(led_claimed){(void)gpio_access(BES_GPIO_WRITE,12,1,&io);}
}
```

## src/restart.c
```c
/* SPDX-License-Identifier: Apache-2.0 */
#include <bes2700_lifecycle.h>

int main(void)
{
	return bes2700_lifecycle_validate();
}
```
